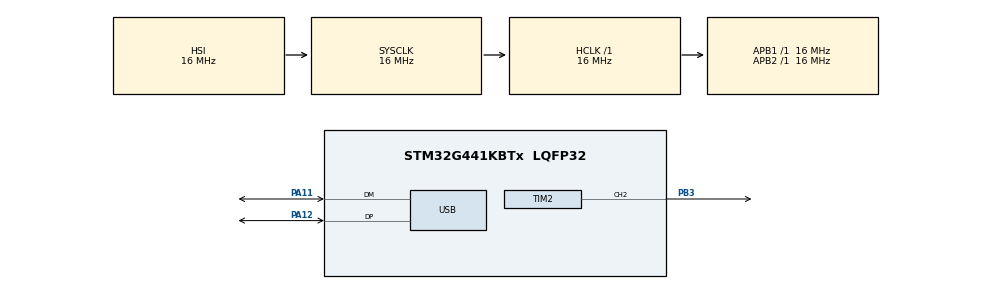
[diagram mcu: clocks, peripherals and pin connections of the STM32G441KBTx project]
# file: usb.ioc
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Mcu.Family=STM32G4
Mcu.Name=STM32G441KBTx
Mcu.Package=LQFP32
NVIC.PriorityGroup=NVIC_PRIORITYGROUP_4
NVIC.USB_LP_IRQn=true\:0\:0\:false\:false\:true\:false\:true
PA11.Mode=Device
PA11.Signal=USB_DM
PA12.Mode=Device
PA12.Signal=USB_DP
PA13.Mode=Serial_Wire
PA13.Signal=SYS_JTMS-SWDIO
PA14.Mode=Serial_Wire
PA14.Signal=SYS_JTCK-SWCLK
PB3.Signal=S_TIM2_CH2
ProjectManager.HeapSize=0x200
ProjectManager.StackSize=0x400
ProjectManager.TargetToolchain=STM32CubeIDE
RCC.AHBFreq_Value=16000000
RCC.APB1Freq_Value=16000000
RCC.APB1TimFreq_Value=16000000
RCC.APB2Freq_Value=16000000
RCC.APB2TimFreq_Value=16000000
RCC.CortexFreq_Value=16000000
RCC.EXTERNAL_CLOCK_VALUE=12288000
RCC.HCLKFreq_Value=16000000
RCC.HSE_VALUE=8000000
RCC.HSI48_VALUE=48000000
RCC.HSI_VALUE=16000000
RCC.LSE_VALUE=32768
RCC.PLLN=12
RCC.PLLQ=RCC_PLLQ_DIV4
RCC.SYSCLKFreq_VALUE=16000000
RCC.USBFreq_Value=48000000
RCC.VCOOutputFreq_Value=192000000
SH.S_TIM2_CH2.0=TIM2_CH2,PWM Generation2 CH2
TIM2.Channel-PWM\ Generation2\ CH2=TIM_CHANNEL_2
TIM2.PeriodNoDither=65535
USB_DEVICE.CLASS_NAME_FS=CDC
USB_DEVICE.VirtualMode=Cdc
USB_DEVICE.VirtualModeFS=Cdc_FS
VP_SYS_VS_DBSignals.Mode=DisableDeadBatterySignals
VP_TIM2_VS_ClockSourceINT.Mode=Internal
VP_USB_DEVICE_VS_USB_DEVICE_CDC_FS.Mode=CDC_FS
board=custom

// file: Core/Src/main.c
/* USER CODE BEGIN Header */
/**
  ******************************************************************************
  * @file           : main.c
  * @brief          : Main program body
  ******************************************************************************
  * @attention
  *
  * Copyright (c) 2022 STMicroelectronics.
  * All rights reserved.
  *
  * This software is licensed under terms that can be found in the LICENSE file
  * in the root directory of this software component.
  * If no LICENSE file comes with this software, it is provided AS-IS.
  *
  ******************************************************************************
  */
/* USER CODE END Header */
#include "main.h"
#include "usb_device.h"

/* USER CODE BEGIN Includes */
#include "usbd_cdc_if.h"

/* USER CODE END Includes */

TIM_HandleTypeDef htim2;

void SystemClock_Config(void);
static void MX_GPIO_Init(void);
static void MX_TIM2_Init(void);

/* USER CODE BEGIN 0 */
typedef struct Command { // (1)
  int16_t speed1;
  int16_t speed2;
  int16_t speed3;
  uint16_t throwerSpeed;
  uint16_t delimiter; // (2)
} Command;

typedef struct Feedback { // (3)
  int16_t speed1;
  int16_t speed2;
  int16_t speed3;
  uint16_t delimiter;
} Feedback;

Command command = {.speed1 = 0, .speed2 = 0, .speed3 = 0, .throwerSpeed = 0, .delimiter = 0}; // (4)
volatile uint8_t isCommandReceived = 0; // (5)

void CDC_On_Receive(uint8_t* buffer, uint32_t* length) { // (6)
  if (*length == sizeof(Command)) { // (7)
    memcpy(&command, buffer, sizeof(Command)); // (8)

    if (command.delimiter == 0xAAAA) { // (9)
      isCommandReceived = 1;
    }
  }
}
/* USER CODE END 0 */

int main(void)
{

  /* MCU Configuration--------------------------------------------------------*/

  /* Reset of all peripherals, Initializes the Flash interface and the Systick. */
  HAL_Init();

  /* Configure the system clock */
  SystemClock_Config();

  /* Initialize all configured peripherals */
  MX_GPIO_Init();
  MX_TIM2_Init();
  MX_USB_Device_Init();
  /* USER CODE BEGIN 2 */
  Feedback feedback = { // (1)
        .speed1 = 1,
        .speed2 = 1,
        .speed3 = 1,
        .delimiter = 0xAAAA
    };
  /* USER CODE END 2 */

  /* Infinite loop */
  while (1)
    {

    /* USER CODE BEGIN 3 */
      if (isCommandReceived == 1) { // (2)
        isCommandReceived = 0;

        feedback.speed1 = 2; // (4)
        feedback.speed2 = 2;
        feedback.speed3 = 2;

        CDC_Transmit_FS(&feedback, sizeof(feedback)); // (5)
      }
    }
  /* USER CODE END 3 */
}

void SystemClock_Config(void)
{
  RCC_OscInitTypeDef RCC_OscInitStruct = {0};
  RCC_ClkInitTypeDef RCC_ClkInitStruct = {0};

  /** Configure the main internal regulator output voltage
  */
  HAL_PWREx_ControlVoltageScaling(PWR_REGULATOR_VOLTAGE_SCALE1);
  /** Initializes the RCC Oscillators according to the specified parameters
  * in the RCC_OscInitTypeDef structure.
  */
  RCC_OscInitStruct.OscillatorType = RCC_OSCILLATORTYPE_HSI;
  RCC_OscInitStruct.HSIState = RCC_HSI_ON;
  RCC_OscInitStruct.HSICalibrationValue = RCC_HSICALIBRATION_DEFAULT;
  RCC_OscInitStruct.PLL.PLLState = RCC_PLL_ON;
  RCC_OscInitStruct.PLL.PLLSource = RCC_PLLSOURCE_HSI;
  RCC_OscInitStruct.PLL.PLLM = RCC_PLLM_DIV1;
  RCC_OscInitStruct.PLL.PLLN = 12;
  RCC_OscInitStruct.PLL.PLLP = RCC_PLLP_DIV2;
  RCC_OscInitStruct.PLL.PLLQ = RCC_PLLQ_DIV4;
  RCC_OscInitStruct.PLL.PLLR = RCC_PLLR_DIV2;
  if (HAL_RCC_OscConfig(&RCC_OscInitStruct) != HAL_OK)
  {
    Error_Handler();
  }
  /** Initializes the CPU, AHB and APB buses clocks
  */
  RCC_ClkInitStruct.ClockType = RCC_CLOCKTYPE_HCLK|RCC_CLOCKTYPE_SYSCLK
                              |RCC_CLOCKTYPE_PCLK1|RCC_CLOCKTYPE_PCLK2;
  RCC_ClkInitStruct.SYSCLKSource = RCC_SYSCLKSOURCE_HSI;
  RCC_ClkInitStruct.AHBCLKDivider = RCC_SYSCLK_DIV1;
  RCC_ClkInitStruct.APB1CLKDivider = RCC_HCLK_DIV1;
  RCC_ClkInitStruct.APB2CLKDivider = RCC_HCLK_DIV1;

  if (HAL_RCC_ClockConfig(&RCC_ClkInitStruct, FLASH_LATENCY_0) != HAL_OK)
  {
    Error_Handler();
  }
}

static void MX_TIM2_Init(void)
{

  TIM_ClockConfigTypeDef sClockSourceConfig = {0};
  TIM_MasterConfigTypeDef sMasterConfig = {0};
  TIM_OC_InitTypeDef sConfigOC = {0};

  htim2.Instance = TIM2;
  htim2.Init.Prescaler = 0;
  htim2.Init.CounterMode = TIM_COUNTERMODE_UP;
  htim2.Init.Period = 65535;
  htim2.Init.ClockDivision = TIM_CLOCKDIVISION_DIV1;
  htim2.Init.AutoReloadPreload = TIM_AUTORELOAD_PRELOAD_DISABLE;
  if (HAL_TIM_Base_Init(&htim2) != HAL_OK)
  {
    Error_Handler();
  }
  sClockSourceConfig.ClockSource = TIM_CLOCKSOURCE_INTERNAL;
  if (HAL_TIM_ConfigClockSource(&htim2, &sClockSourceConfig) != HAL_OK)
  {
    Error_Handler();
  }
  if (HAL_TIM_PWM_Init(&htim2) != HAL_OK)
  {
    Error_Handler();
  }
  sMasterConfig.MasterOutputTrigger = TIM_TRGO_RESET;
  sMasterConfig.MasterSlaveMode = TIM_MASTERSLAVEMODE_DISABLE;
  if (HAL_TIMEx_MasterConfigSynchronization(&htim2, &sMasterConfig) != HAL_OK)
  {
    Error_Handler();
  }
  sConfigOC.OCMode = TIM_OCMODE_PWM1;
  sConfigOC.Pulse = 0;
  sConfigOC.OCPolarity = TIM_OCPOLARITY_HIGH;
  sConfigOC.OCFastMode = TIM_OCFAST_DISABLE;
  if (HAL_TIM_PWM_ConfigChannel(&htim2, &sConfigOC, TIM_CHANNEL_2) != HAL_OK)
  {
    Error_Handler();
  }
  HAL_TIM_MspPostInit(&htim2);

}

static void MX_GPIO_Init(void)
{

  /* GPIO Ports Clock Enable */
  __HAL_RCC_GPIOA_CLK_ENABLE();
  __HAL_RCC_GPIOB_CLK_ENABLE();

}

void Error_Handler(void)
{
  __disable_irq();
  while (1)
  {
  }
}
